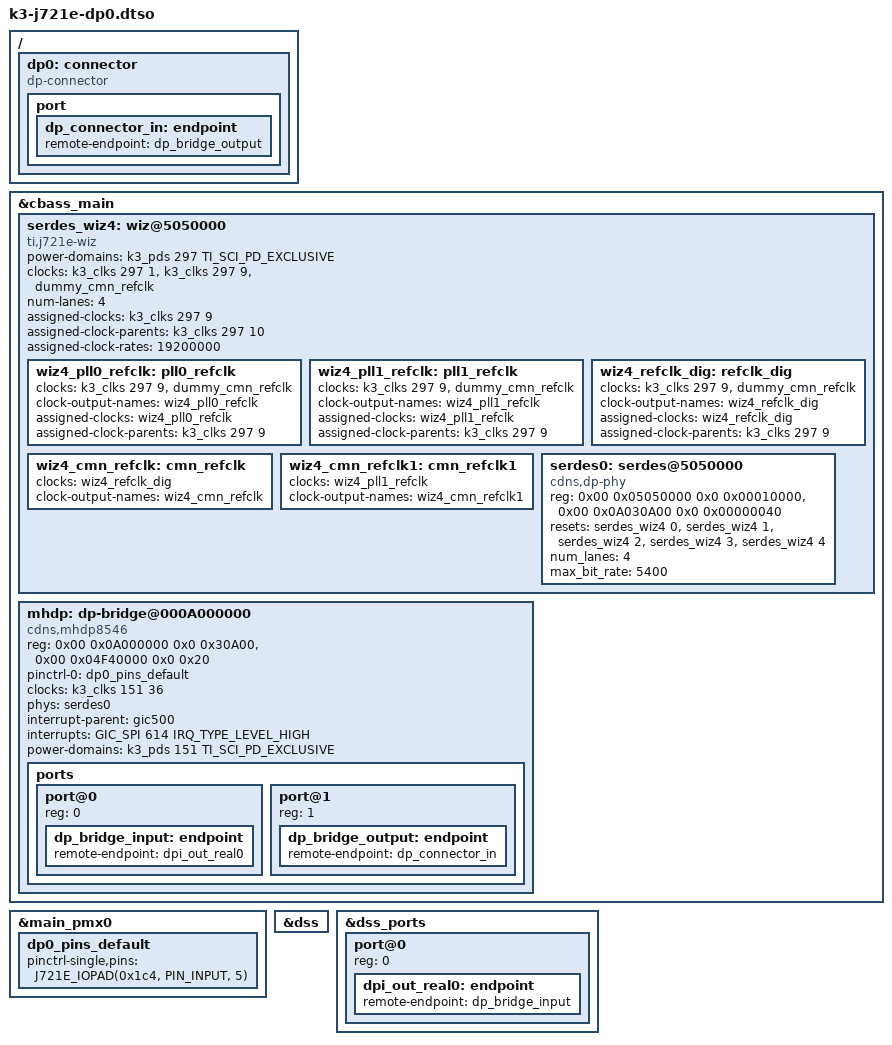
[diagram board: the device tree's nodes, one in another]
// SPDX-License-Identifier: GPL-2.0
/*
 * J7 DisplayPort
 *
 * Copyright (C) 2019 Texas Instruments Incorporated - http://www.ti.com/
 */

/dts-v1/;
/plugin/;

#include <dt-bindings/pinctrl/k3.h>
#include <dt-bindings/interrupt-controller/irq.h>
#include <dt-bindings/interrupt-controller/arm-gic.h>
#include <dt-bindings/soc/ti,sci_pm_domain.h>

/ {
  fragment@101 {
	target-path = "/";

	__overlay__ {
		/* XXX not used, maybe we should drop this */
		dp0: connector {
			compatible = "dp-connector"; /* No such binding exists yet.. */

			port {
				dp_connector_in: endpoint {
					remote-endpoint = <&dp_bridge_output>;
				};
			};
		};
	};
  };
};

&cbass_main {
	#address-cells = <2>;
	#size-cells = <2>;

	serdes_wiz4: wiz@5050000 {
		compatible = "ti,j721e-wiz";
		#address-cells = <2>;
		#size-cells = <2>;
		power-domains = <&k3_pds 297 TI_SCI_PD_EXCLUSIVE>;
		clocks = <&k3_clks 297 1>, <&k3_clks 297 9>, <&dummy_cmn_refclk>;
		clock-names = "fck", "core_ref_clk", "ext_ref_clk";
		num-lanes = <4>;
		#reset-cells = <1>;
		ranges;

		assigned-clocks = <&k3_clks 297 9>;
		assigned-clock-parents = <&k3_clks 297 10>;
		assigned-clock-rates = <19200000>;

		wiz4_pll0_refclk: pll0_refclk {
			clocks = <&k3_clks 297 9>, <&dummy_cmn_refclk>;
			clock-output-names = "wiz4_pll0_refclk";
			#clock-cells = <0>;
			assigned-clocks = <&wiz4_pll0_refclk>;
			assigned-clock-parents = <&k3_clks 297 9>;
		};

		wiz4_pll1_refclk: pll1_refclk {
			clocks = <&k3_clks 297 9>, <&dummy_cmn_refclk>;
			clock-output-names = "wiz4_pll1_refclk";
			#clock-cells = <0>;
			assigned-clocks = <&wiz4_pll1_refclk>;
			assigned-clock-parents = <&k3_clks 297 9>;
		};

		wiz4_refclk_dig: refclk_dig {
			clocks = <&k3_clks 297 9>, <&dummy_cmn_refclk>;
			clock-output-names = "wiz4_refclk_dig";
			#clock-cells = <0>;
			assigned-clocks = <&wiz4_refclk_dig>;
			assigned-clock-parents = <&k3_clks 297 9>;
		};

		wiz4_cmn_refclk: cmn_refclk {
			clocks = <&wiz4_refclk_dig>;
			clock-output-names = "wiz4_cmn_refclk";
			#clock-cells = <0>;
		};

		wiz4_cmn_refclk1: cmn_refclk1 {
			clocks = <&wiz4_pll1_refclk>;
			clock-output-names = "wiz4_cmn_refclk1";
			#clock-cells = <0>;
		};

		serdes0: serdes@5050000 {
			/* XXX we also map EDP0 registers here as the PHY driver needs those... */
			compatible = "cdns,dp-phy";
			reg = <0x00 0x05050000 0x0 0x00010000>, /* SERDES_10G0 */
			      <0x00 0x0A030A00 0x0 0x00000040>; /* DSS_EDP0_V2A_CORE_VP_REGS_APB + 30A00 */

			resets = <&serdes_wiz4 0>, <&serdes_wiz4 1>,
				 <&serdes_wiz4 2>, <&serdes_wiz4 3>,
				 <&serdes_wiz4 4>;

			num_lanes = <4>;
			max_bit_rate = <5400>;
			#phy-cells = <0>;
		};
	};

	mhdp: dp-bridge@000A000000 {
		compatible = "cdns,mhdp8546";
		reg = <0x00 0x0A000000 0x0 0x30A00>, /* DSS_EDP0_V2A_CORE_VP_REGS_APB - upto PHY mapped area */
		      <0x00 0x04F40000 0x0 0x20>;    /* DSS_EDP0_INTG_CFG_VP */

		pinctrl-names = "default";
		pinctrl-0 = <&dp0_pins_default>;

		clocks = <&k3_clks 151 36>;

		phys = <&serdes0>;
		phy-names = "dpphy";

		interrupt-parent = <&gic500>;
		interrupts = <GIC_SPI 614 IRQ_TYPE_LEVEL_HIGH>;

		power-domains = <&k3_pds 151 TI_SCI_PD_EXCLUSIVE>;

		/* TODO: No audio config yet */
		/* TODO: Pinmux for eDP output pins */

		ports {
			#address-cells = <1>;
			#size-cells = <0>;

			port@0 {
				reg = <0>;
				dp_bridge_input: endpoint {
					remote-endpoint = <&dpi_out_real0>;
				};
			};

			port@1 {
				reg = <1>;
				dp_bridge_output: endpoint {
					remote-endpoint = <&dp_connector_in>;
				};
			};
		};
	};
};

&main_pmx0 {
	dp0_pins_default: dp0_pins_default {
		pinctrl-single,pins = <
			J721E_IOPAD(0x1c4, PIN_INPUT, 5) /* SPI0_CS1.DP0_HPD */
		>;
	};
};

&dss {
	status = "ok";
};

&dss_ports {
	#address-cells = <1>;
	#size-cells = <0>;

	port@0 {
		reg = <0>;

		dpi_out_real0: endpoint {
			remote-endpoint = <&dp_bridge_input>;
		};
	};
};
